# R7FA6T2BD register map
Vendor: Renesas Electronics Corporation; Series: RA6; File version: 1.40.00
CPU: CM33 r0p4, little endian, MPU, FPU, VTOR, 4 interrupt priority bits, 96 interrupts
Registers are 32-bit, read-write, reset 0x0 unless marked. A register's access mark holds for its fields unless they carry their own. Offsets are from the block's base; [hi:lo] are bit positions; {n}, {i} and the like mark numbered series; 'fields as' and 'values as' point back to an identical list.

## PFS_B — Pmn Pin Function Control Register
Base 0x4001F800
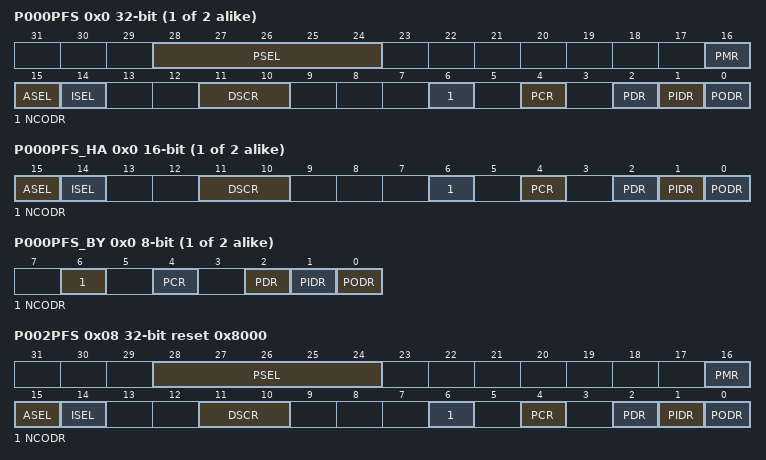
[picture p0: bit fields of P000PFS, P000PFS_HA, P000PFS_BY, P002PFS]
{0x0+4i} P00{i}PFS (i=0..1) (reset mask 0xFFFFFFFD) — Port 00{i} Pin Function Select Register
  [28:24] PSEL — Peripheral Select
  [16] PMR — Port Mode Control
    0=Used as a general I/O pin; 1=Used as an I/O port for peripheral functions
  [15] ASEL — Analog Input Enable
    0=Not used as an analog pin; 1=Used as an analog pin
  [14] ISEL — IRQ Input Enable
    0=Not used as an IRQn input pin; 1=Used as an IRQn input pin
  [11:10] DSCR — Port Drive Capability
    0=Low drive; 1=Middle drive; 2=High-speed high-drive / High current drive; 3=High drive
  [6] NCODR — N-Channel Open-Drain Control
    0=CMOS output; 1=NMOS open-drain output
  [4] PCR — Pull-up Control
    0=Disable input pull-up; 1=Enable input pull-up
  [2] PDR — Port Direction
    0=Input (functions as an input pin); 1=Output (functions as an output pin)
  [1] PIDR ro — Pmn State
    0=Low level; 1=High level
  [0] PODR — Port Output Data
    0=Low output; 1=High output
{0x0+4i} P00{i}PFS_HA (i=0..1) 16-bit (reset mask 0xFFFD) (alternate view of P00{i}PFS) — Port 00{i} Pin Function Select Register
  [15] ASEL — Analog Input Enable
    0=Not used as an analog pin; 1=Used as an analog pin
  [14] ISEL — IRQ Input Enable
    0=Not used as an IRQn input pin; 1=Used as an IRQn input pin
  [11:10] DSCR — Port Drive Capability
    values as P000PFS.DSCR
  [6] NCODR — N-Channel Open-Drain Control
    0=CMOS output; 1=NMOS open-drain output
  [4] PCR — Pull-up Control
    0=Disable input pull-up; 1=Enable input pull-up
  [2] PDR — Port Direction
    values as P000PFS.PDR
  [1] PIDR ro — Pmn State
    0=Low level; 1=High level
  [0] PODR — Port Output Data
    0=Low output; 1=High output
{0x0+4i} P00{i}PFS_BY (i=0..1) 8-bit (reset mask 0xFD) (alternate view of P00{i}PFS) — Port 00{i} Pin Function Select Register
  [6] NCODR — N-Channel Open-Drain Control
    0=CMOS output; 1=NMOS open-drain output
  [4] PCR — Pull-up Control
    0=Disable input pull-up; 1=Enable input pull-up
  [2] PDR — Port Direction
    values as P000PFS.PDR
  [1] PIDR ro — Pmn State
    0=Low level; 1=High level
  [0] PODR — Port Output Data
    0=Low output; 1=High output
0x08 P002PFS reset 0x8000 (reset mask 0xFFFFFFFD) — Port 002 Pin Function Select Register
  fields as P000PFS
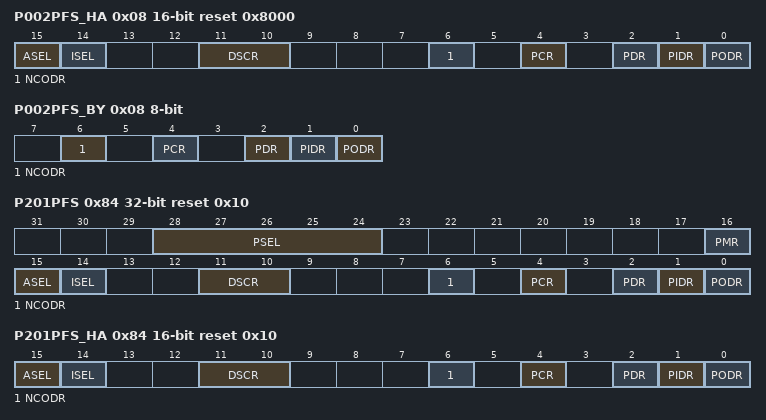
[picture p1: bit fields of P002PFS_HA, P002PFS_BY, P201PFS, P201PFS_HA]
0x08 P002PFS_HA 16-bit reset 0x8000 (reset mask 0xFFFD) (alternate view of P002PFS) — Port 002 Pin Function Select Register
  fields as P000PFS_HA
0x08 P002PFS_BY 8-bit (reset mask 0xFD) (alternate view of P002PFS) — Port 002 Pin Function Select Register
  fields as P000PFS_BY
0x84 P201PFS reset 0x10 (reset mask 0xFFFFFFFD) — Port 201 Pin Function Select Register
  fields as P000PFS
0x84 P201PFS_HA 16-bit reset 0x10 (reset mask 0xFFFD) (alternate view of P201PFS) — Port 201 Pin Function Select Register
  fields as P000PFS_HA
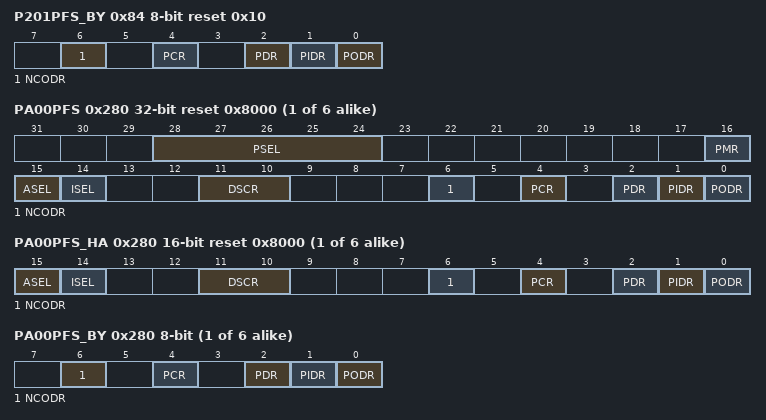
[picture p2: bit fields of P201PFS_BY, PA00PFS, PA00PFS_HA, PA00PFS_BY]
0x84 P201PFS_BY 8-bit reset 0x10 (reset mask 0xFD) (alternate view of P201PFS) — Port 201 Pin Function Select Register
  fields as P000PFS_BY
{0x280+4i} PA0{i}PFS (i=0..5) reset 0x8000 (reset mask 0xFFFFFFFD) — Port A0{i} Pin Function Select Register
  fields as P000PFS
{0x280+4i} PA0{i}PFS_HA (i=0..5) 16-bit reset 0x8000 (reset mask 0xFFFD) (alternate view of PA0{i}PFS) — Port A0{i} Pin Function Select Register
  fields as P000PFS_HA
{0x280+4i} PA0{i}PFS_BY (i=0..5) 8-bit (reset mask 0xFD) (alternate view of PA0{i}PFS) — Port A0{i} Pin Function Select Register
  fields as P000PFS_BY
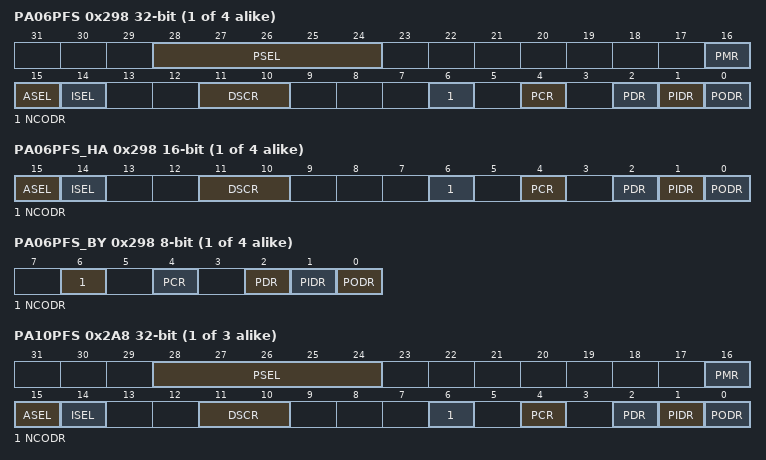
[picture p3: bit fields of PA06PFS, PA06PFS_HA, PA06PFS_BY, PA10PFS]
{0x280+4i} PA0{i}PFS (i=6..9) (reset mask 0xFFFFFFFD) — Port A0{i} Pin Function Select Register
  fields as P000PFS
{0x280+4i} PA0{i}PFS_HA (i=6..9) 16-bit (reset mask 0xFFFD) (alternate view of PA0{i}PFS) — Port A0{i} Pin Function Select Register
  fields as P000PFS_HA
{0x280+4i} PA0{i}PFS_BY (i=6..9) 8-bit (reset mask 0xFD) (alternate view of PA0{i}PFS) — Port A0{i} Pin Function Select Register
  fields as P000PFS_BY
{0x2A8+4i} PA1{i}PFS (i=0..2) (reset mask 0xFFFFFFFD) — Port A1{i} Pin Function Select Register
  fields as P000PFS
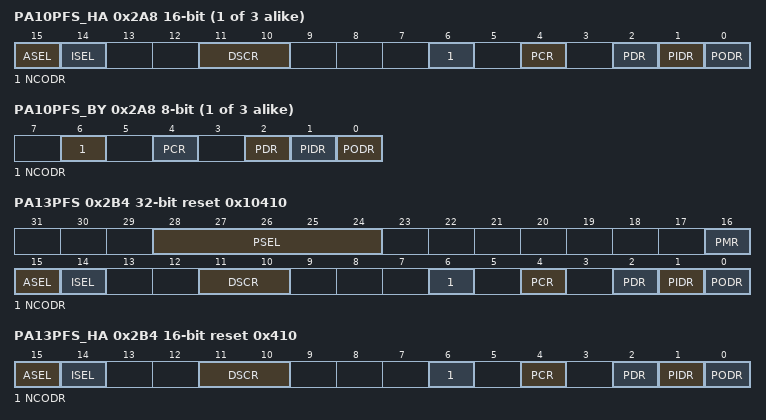
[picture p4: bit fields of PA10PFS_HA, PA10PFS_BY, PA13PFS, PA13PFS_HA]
{0x2A8+4i} PA1{i}PFS_HA (i=0..2) 16-bit (reset mask 0xFFFD) (alternate view of PA1{i}PFS) — Port A1{i} Pin Function Select Register
  fields as P000PFS_HA
{0x2A8+4i} PA1{i}PFS_BY (i=0..2) 8-bit (reset mask 0xFD) (alternate view of PA1{i}PFS) — Port A1{i} Pin Function Select Register
  fields as P000PFS_BY
0x2B4 PA13PFS reset 0x10410 (reset mask 0xFFFFFFFD) — Port A13 Pin Function Select Register
  fields as P000PFS
0x2B4 PA13PFS_HA 16-bit reset 0x410 (reset mask 0xFFFD) (alternate view of PA13PFS) — Port A13 Pin Function Select Register
  fields as P000PFS_HA
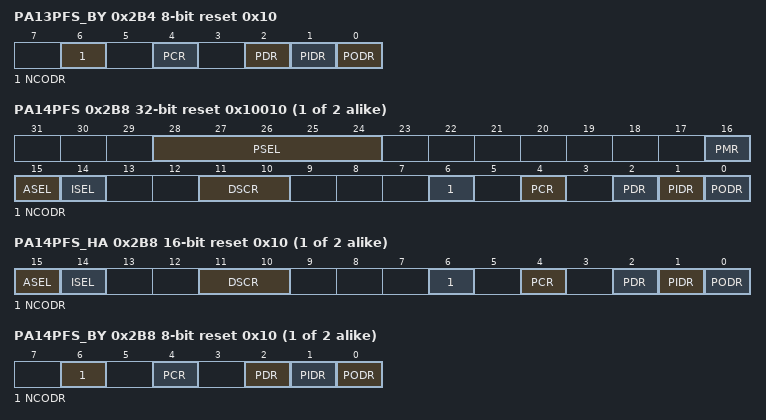
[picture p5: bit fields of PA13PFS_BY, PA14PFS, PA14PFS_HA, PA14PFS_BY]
0x2B4 PA13PFS_BY 8-bit reset 0x10 (reset mask 0xFD) (alternate view of PA13PFS) — Port A13 Pin Function Select Register
  fields as P000PFS_BY
{0x2A8+4i} PA1{i}PFS (i=4..5) reset 0x10010 (reset mask 0xFFFFFFFD) — Port A1{i} Pin Function Select Register
  fields as P000PFS
{0x2A8+4i} PA1{i}PFS_HA (i=4..5) 16-bit reset 0x10 (reset mask 0xFFFD) (alternate view of PA1{i}PFS) — Port A1{i} Pin Function Select Register
  fields as P000PFS_HA
{0x2A8+4i} PA1{i}PFS_BY (i=4..5) 8-bit reset 0x10 (reset mask 0xFD) (alternate view of PA1{i}PFS) — Port A1{i} Pin Function Select Register
  fields as P000PFS_BY
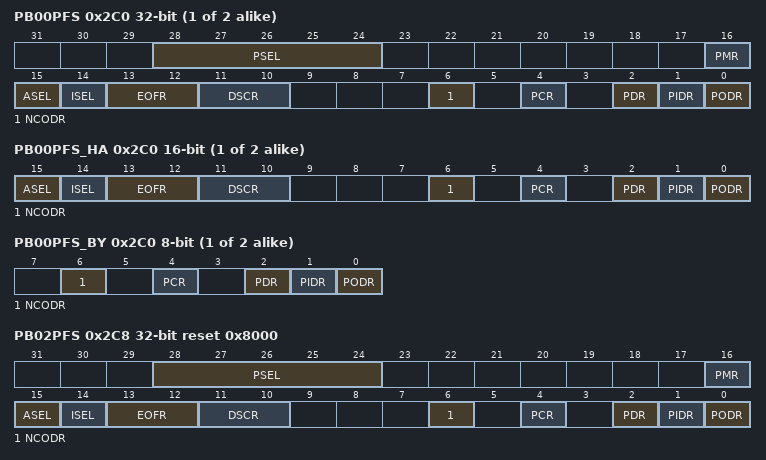
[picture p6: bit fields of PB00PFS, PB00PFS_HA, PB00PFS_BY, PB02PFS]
{0x2C0+4i} PB0{i}PFS (i=0..1) (reset mask 0xFFFFFFFD) — Port B0{i} Pin Function Select Register
  [28:24] PSEL — Peripheral Select
  [16] PMR — Port Mode Control
    values as P000PFS.PMR
  [15] ASEL — Analog Input Enable
    0=Not used as an analog pin; 1=Used as an analog pin
  [14] ISEL — IRQ Input Enable
    0=Not used as an IRQn input pin; 1=Used as an IRQn input pin
  [13:12] EOFR — Event on Falling/Event on Rising
    0=Don't care; 1=Detect rising edge; 2=Detect falling edge; 3=Detect both edges
  [11:10] DSCR — Port Drive Capability
    values as P000PFS.DSCR
  [6] NCODR — N-Channel Open-Drain Control
    0=CMOS output; 1=NMOS open-drain output
  [4] PCR — Pull-up Control
    0=Disable input pull-up; 1=Enable input pull-up
  [2] PDR — Port Direction
    values as P000PFS.PDR
  [1] PIDR ro — Pmn State
    0=Low level; 1=High level
  [0] PODR — Port Output Data
    0=Low output; 1=High output
{0x2C0+4i} PB0{i}PFS_HA (i=0..1) 16-bit (reset mask 0xFFFD) (alternate view of PB0{i}PFS) — Port B0{i} Pin Function Select Register
  [15] ASEL — Analog Input Enable
    0=Not used as an analog pin; 1=Used as an analog pin
  [14] ISEL — IRQ Input Enable
    0=Not used as an IRQn input pin; 1=Used as an IRQn input pin
  [13:12] EOFR — Event on Falling/Event on Rising
    values as PB00PFS.EOFR
  [11:10] DSCR — Port Drive Capability
    values as P000PFS.DSCR
  [6] NCODR — N-Channel Open-Drain Control
    0=CMOS output; 1=NMOS open-drain output
  [4] PCR — Pull-up Control
    0=Disable input pull-up; 1=Enable input pull-up
  [2] PDR — Port Direction
    values as P000PFS.PDR
  [1] PIDR ro — Pmn State
    0=Low level; 1=High level
  [0] PODR — Port Output Data
    0=Low output; 1=High output
{0x2C0+4i} PB0{i}PFS_BY (i=0..1) 8-bit (reset mask 0xFD) (alternate view of PB0{i}PFS) — Port B0{i} Pin Function Select Register
  fields as P000PFS_BY
0x2C8 PB02PFS reset 0x8000 (reset mask 0xFFFEFBED) — Port B02 Pin Function Select Register
  fields as PB00PFS
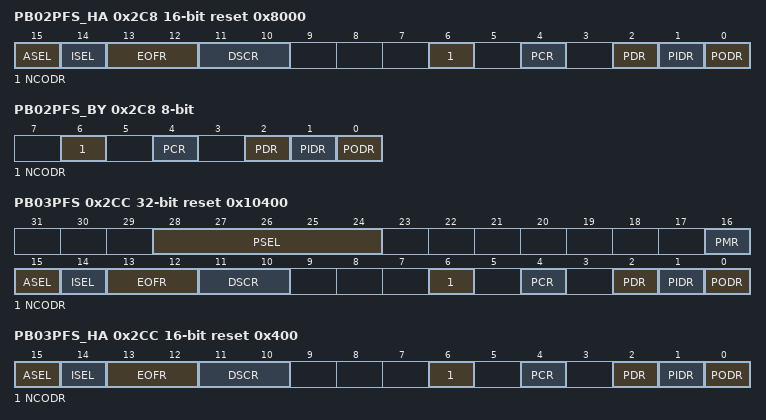
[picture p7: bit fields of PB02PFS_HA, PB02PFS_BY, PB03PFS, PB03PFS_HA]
0x2C8 PB02PFS_HA 16-bit reset 0x8000 (reset mask 0xFBED) (alternate view of PB02PFS) — Port B02 Pin Function Select Register
  fields as PB00PFS_HA
0x2C8 PB02PFS_BY 8-bit (reset mask 0xED) (alternate view of PB02PFS) — Port B02 Pin Function Select Register
  fields as P000PFS_BY
0x2CC PB03PFS reset 0x10400 (reset mask 0xFFFFFFFD) — Port B03 Pin Function Select Register
  fields as PB00PFS
0x2CC PB03PFS_HA 16-bit reset 0x400 (reset mask 0xFFFD) (alternate view of PB03PFS) — Port B03 Pin Function Select Register
  fields as PB00PFS_HA
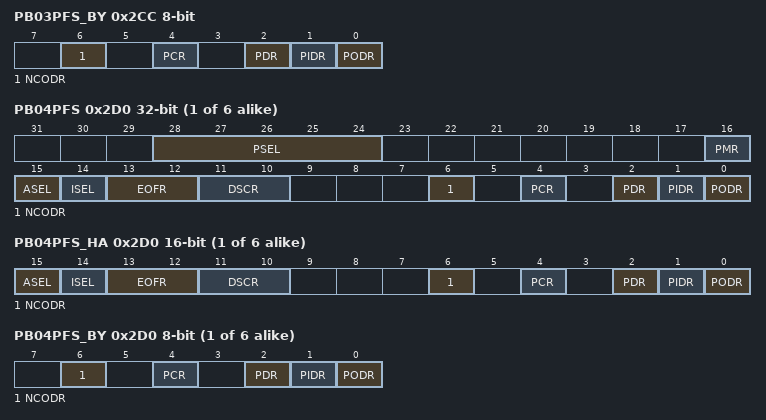
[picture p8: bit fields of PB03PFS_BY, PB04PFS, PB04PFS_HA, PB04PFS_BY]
0x2CC PB03PFS_BY 8-bit (reset mask 0xFD) (alternate view of PB03PFS) — Port B03 Pin Function Select Register
  fields as P000PFS_BY
{0x2C0+4i} PB0{i}PFS (i=4..9) (reset mask 0xFFFFFFFD) — Port B0{i} Pin Function Select Register
  fields as PB00PFS
{0x2C0+4i} PB0{i}PFS_HA (i=4..9) 16-bit (reset mask 0xFFFD) (alternate view of PB0{i}PFS) — Port B0{i} Pin Function Select Register
  fields as PB00PFS_HA
{0x2C0+4i} PB0{i}PFS_BY (i=4..9) 8-bit (reset mask 0xFD) (alternate view of PB0{i}PFS) — Port B0{i} Pin Function Select Register
  fields as P000PFS_BY
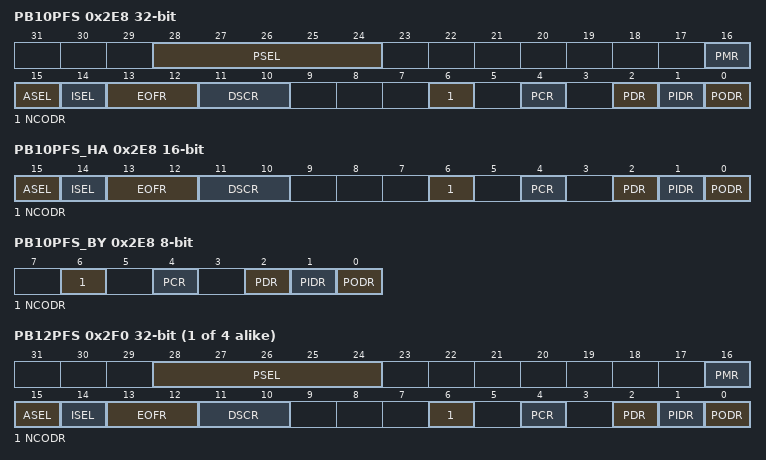
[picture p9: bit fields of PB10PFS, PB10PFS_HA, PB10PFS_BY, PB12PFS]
0x2E8 PB10PFS (reset mask 0xFFFE7BED) — Port B10 Pin Function Select Register
  fields as PB00PFS
0x2E8 PB10PFS_HA 16-bit (reset mask 0x7BED) (alternate view of PB10PFS) — Port B10 Pin Function Select Register
  fields as PB00PFS_HA
0x2E8 PB10PFS_BY 8-bit (reset mask 0xED) (alternate view of PB10PFS) — Port B10 Pin Function Select Register
  fields as P000PFS_BY
{0x2E8+4i} PB1{i}PFS (i=2..5) (reset mask 0xFFFE7BED) — Port B1{i} Pin Function Select Register
  fields as PB00PFS
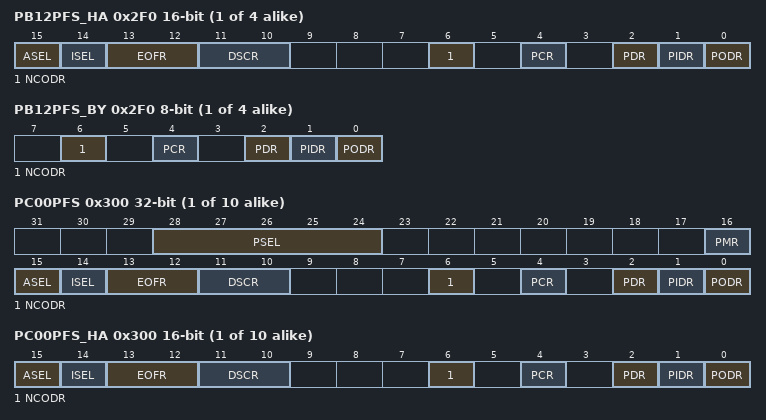
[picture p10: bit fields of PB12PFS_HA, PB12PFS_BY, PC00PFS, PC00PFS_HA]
{0x2E8+4i} PB1{i}PFS_HA (i=2..5) 16-bit (reset mask 0x7BED) (alternate view of PB1{i}PFS) — Port B1{i} Pin Function Select Register
  fields as PB00PFS_HA
{0x2E8+4i} PB1{i}PFS_BY (i=2..5) 8-bit (reset mask 0xED) (alternate view of PB1{i}PFS) — Port B1{i} Pin Function Select Register
  fields as P000PFS_BY
{0x300+4i} PC0{i}PFS (i=0..9) (reset mask 0xFFFFFFFD) — Port C0{i} Pin Function Select Register
  fields as PB00PFS
{0x300+4i} PC0{i}PFS_HA (i=0..9) 16-bit (reset mask 0xFFFD) (alternate view of PC0{i}PFS) — Port C0{i} Pin Function Select Register
  fields as PB00PFS_HA
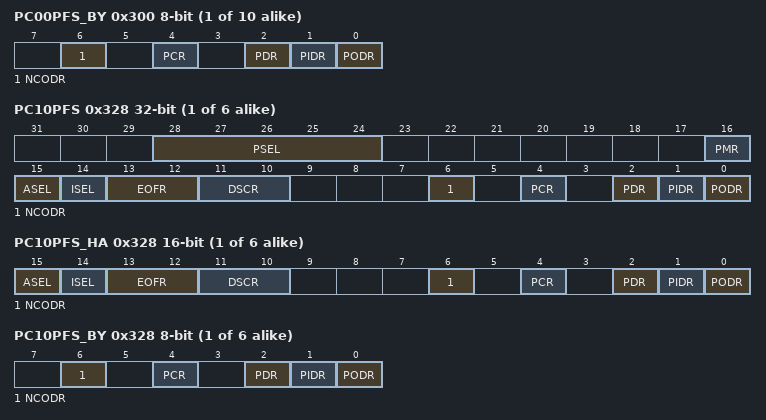
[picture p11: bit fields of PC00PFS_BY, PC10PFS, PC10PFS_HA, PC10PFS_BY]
{0x300+4i} PC0{i}PFS_BY (i=0..9) 8-bit (reset mask 0xFD) (alternate view of PC0{i}PFS) — Port C0{i} Pin Function Select Register
  fields as P000PFS_BY
{0x328+4i} PC1{i}PFS (i=0..5) (reset mask 0xFFFFFFFD) — Port C1{i} Pin Function Select Register
  fields as PB00PFS
{0x328+4i} PC1{i}PFS_HA (i=0..5) 16-bit (reset mask 0xFFFD) (alternate view of PC1{i}PFS) — Port C1{i} Pin Function Select Register
  fields as PB00PFS_HA
{0x328+4i} PC1{i}PFS_BY (i=0..5) 8-bit (reset mask 0xFD) (alternate view of PC1{i}PFS) — Port C1{i} Pin Function Select Register
  fields as P000PFS_BY
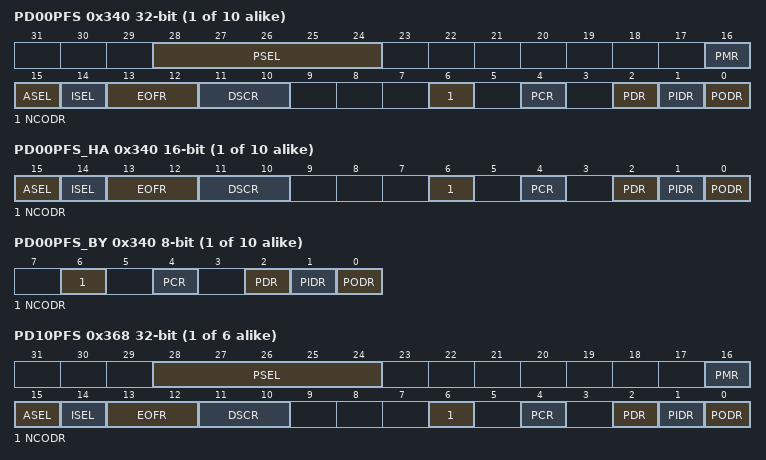
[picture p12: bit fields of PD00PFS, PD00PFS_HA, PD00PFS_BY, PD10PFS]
{0x340+4i} PD0{i}PFS (i=0..9) (reset mask 0xFFFFFFFD) — Port D0{i} Pin Function Select Register
  fields as PB00PFS
{0x340+4i} PD0{i}PFS_HA (i=0..9) 16-bit (reset mask 0xFFFD) (alternate view of PD0{i}PFS) — Port D0{i} Pin Function Select Register
  fields as PB00PFS_HA
{0x340+4i} PD0{i}PFS_BY (i=0..9) 8-bit (reset mask 0xFD) (alternate view of PD0{i}PFS) — Port D0{i} Pin Function Select Register
  fields as P000PFS_BY
{0x368+4i} PD1{i}PFS (i=0..5) (reset mask 0xFFFFFFFD) — Port D1{i} Pin Function Select Register
  fields as PB00PFS
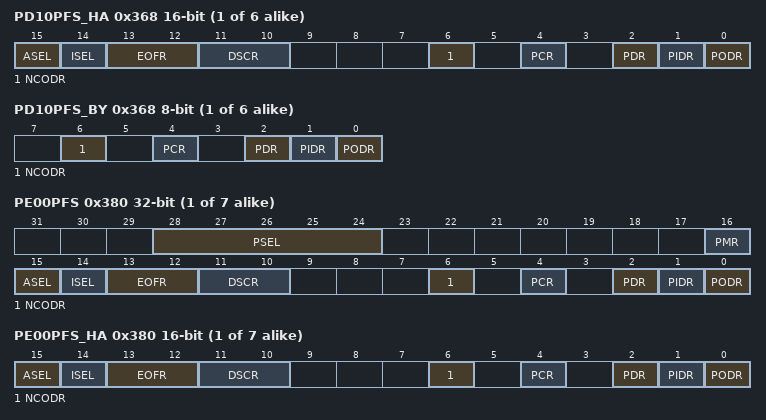
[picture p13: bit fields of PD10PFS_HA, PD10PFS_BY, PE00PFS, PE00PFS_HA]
{0x368+4i} PD1{i}PFS_HA (i=0..5) 16-bit (reset mask 0xFFFD) (alternate view of PD1{i}PFS) — Port D1{i} Pin Function Select Register
  fields as PB00PFS_HA
{0x368+4i} PD1{i}PFS_BY (i=0..5) 8-bit (reset mask 0xFD) (alternate view of PD1{i}PFS) — Port D1{i} Pin Function Select Register
  fields as P000PFS_BY
{0x380+4i} PE0{i}PFS (i=0..6) (reset mask 0xFFFFFFFD) — Port E0{i} Pin Function Select Register
  fields as PB00PFS
{0x380+4i} PE0{i}PFS_HA (i=0..6) 16-bit (reset mask 0xFFFD) (alternate view of PE0{i}PFS) — Port E0{i} Pin Function Select Register
  fields as PB00PFS_HA
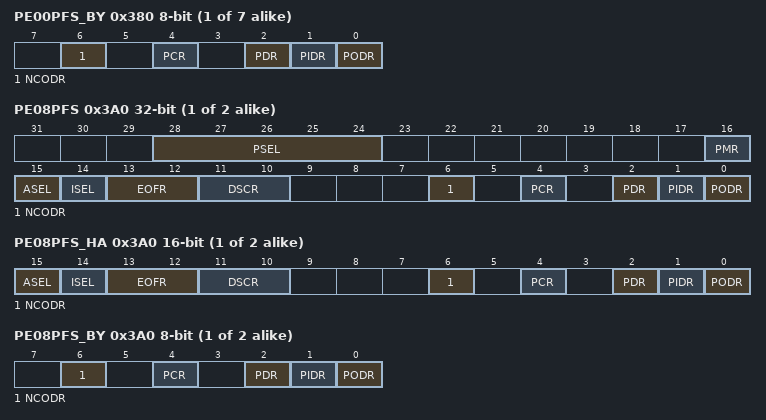
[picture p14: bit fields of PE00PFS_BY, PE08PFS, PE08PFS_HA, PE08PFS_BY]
{0x380+4i} PE0{i}PFS_BY (i=0..6) 8-bit (reset mask 0xFD) (alternate view of PE0{i}PFS) — Port E0{i} Pin Function Select Register
  fields as P000PFS_BY
{0x380+4i} PE0{i}PFS (i=8..9) (reset mask 0xFFFFFFFD) — Port E0{i} Pin Function Select Register
  fields as PB00PFS
{0x380+4i} PE0{i}PFS_HA (i=8..9) 16-bit (reset mask 0xFFFD) (alternate view of PE0{i}PFS) — Port E0{i} Pin Function Select Register
  fields as PB00PFS_HA
{0x380+4i} PE0{i}PFS_BY (i=8..9) 8-bit (reset mask 0xFD) (alternate view of PE0{i}PFS) — Port E0{i} Pin Function Select Register
  fields as P000PFS_BY
{0x3A8+4i} PE1{i}PFS (i=0..5) (reset mask 0xFFFFFFFD) — Port E1{i} Pin Function Select Register
  fields as PB00PFS
{0x3A8+4i} PE1{i}PFS_HA (i=0..5) 16-bit (reset mask 0xFFFD) (alternate view of PE1{i}PFS) — Port E1{i} Pin Function Select Register
  fields as PB00PFS_HA
{0x3A8+4i} PE1{i}PFS_BY (i=0..5) 8-bit (reset mask 0xFD) (alternate view of PE1{i}PFS) — Port E1{i} Pin Function Select Register
  fields as P000PFS_BY
0x50C PWPR 8-bit reset 0x80 — Write-Protect Register
  [7] B0WI — PFSWE Bit Write Disable
    0=Writing to the PFSWE bit is enabled; 1=Writing to the PFSWE bit is disabled
  [6] PFSWE — PmnPFS Register Write Enable
    0=Writing to the PmnPFS register is disabled; 1=Writing to the PmnPFS register is enabled
0x514 PWPRS 8-bit reset 0x80 — Write-Protect Register for Secure
  [7] B0WI — PFSWE Bit Write Disable
    0=Enable writes the PFSWE bit; 1=Disable writes to the PFSWE bit
  [6] PFSWE — PmnPFS Register Write Enable
    0=Disable writes to the PmnPFS register; 1=Enable writes to the PmnPFS register
0x530 P0SAR 16-bit reset 0xFFFF — Port 0 Security Attribution register
  [15:0] PMNSA — Pmn Security Attribution
    0=Secure; 1=Non Secure
0x538 P2SAR 16-bit reset 0xFFFF — Port 2 Security Attribution register
  [15:0] PMNSA — Pmn Security Attribution
    0=Secure; 1=Non Secure
0x558 PASAR 16-bit reset 0xFFFF — Port A Security Attribution register
  [15:0] PMNSA — Pmn Security Attribution
    0=Secure; 1=Non Secure
0x55C PBSAR 16-bit reset 0xFFFF — Port B Security Attribution register
  [15:0] PMNSA — Pmn Security Attribution
    0=Secure; 1=Non Secure
0x560 PCSAR 16-bit reset 0xFFFF — Port C Security Attribution register
  [15:0] PMNSA — Pmn Security Attribution
    0=Secure; 1=Non Secure
0x564 PDSAR 16-bit reset 0xFFFF — Port D Security Attribution register
  [15:0] PMNSA — Pmn Security Attribution
    0=Secure; 1=Non Secure
0x568 PESAR 16-bit reset 0xFFFF — Port E Security Attribution register
  [15:0] PMNSA — Pmn Security Attribution
    0=Secure; 1=Non Secure
